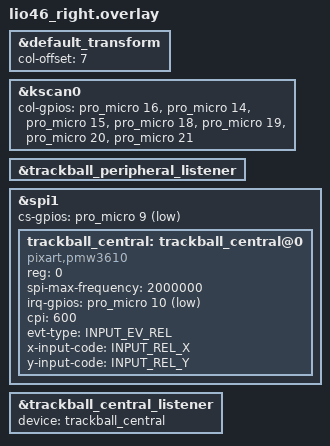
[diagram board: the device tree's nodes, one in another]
#include "lio46.dtsi"

&default_transform {
    col-offset = <7>;
};

&kscan0 {
    col-gpios
        = <&pro_micro 16 GPIO_ACTIVE_HIGH> // 010
        , <&pro_micro 14 GPIO_ACTIVE_HIGH> // 111
        , <&pro_micro 15 GPIO_ACTIVE_HIGH> // 113
        , <&pro_micro 18 GPIO_ACTIVE_HIGH> // 115
        , <&pro_micro 19 GPIO_ACTIVE_HIGH> // 002
        , <&pro_micro 20 GPIO_ACTIVE_HIGH> // 029
        , <&pro_micro 21 GPIO_ACTIVE_HIGH> // 031
        ;
};


&trackball_peripheral_listener {
    status = "okay";
};

#include <zephyr/dt-bindings/input/input-event-codes.h>
&spi1 {
    cs-gpios = <&pro_micro 9 GPIO_ACTIVE_LOW>;

    trackball_central: trackball_central@0 {
        status = "okay";
        compatible = "pixart,pmw3610";
        reg = <0>;
        spi-max-frequency = <2000000>;
        irq-gpios = <&pro_micro 10 (GPIO_ACTIVE_LOW | GPIO_PULL_UP)>;
        cpi = <600>;
        evt-type = <INPUT_EV_REL>;
        x-input-code = <INPUT_REL_X>;
        y-input-code = <INPUT_REL_Y>;
    };
};

// Overrides for the input listener node
&trackball_central_listener {
    status = "okay";
    device = <&trackball_central>;
};
